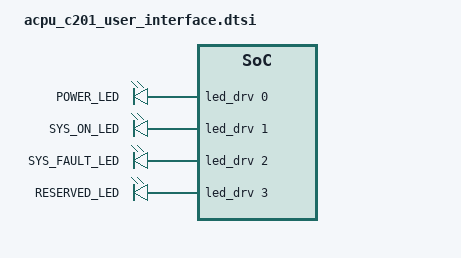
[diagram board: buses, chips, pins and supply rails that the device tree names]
/*
 * Copyright (c) 2021 Acme CPU
 *
 * SPDX-License-Identifier: Apache-2.0
 */

/ {
  ui-leds {
    compatible = "pwm-leds";

    p09_yellow_led: led-drv-0 {
      pwms = <&led_drv 0>;
      label = "POWER_LED";
    };

    p15_blue_led: led-drv-1 {
      pwms = <&led_drv 1>;
      label = "SYS_ON_LED";
    };

    p23_red_led: led-drv-2 {
      pwms = <&led_drv 2>;
      label = "SYS_FAULT_LED";
    };

    d11_green_led: led-drv-3 {
      pwms = <&led_drv 3>;
      label = "RESERVED_LED";
    };

  };
};


/*
 * This section describes parameters to initialize individual pins of the DIO_3 port expander with
 * during the system boots up. It is intended to be used by BSP GPIO Device Driver.
 */


/*
 *  Remaining pins of the DIO_3 port expander are dedicated to serve on-board peripheral devices.
 *  Description of those pins is presented in acme_cpu_c201_gpios.dtsi file
 */


&dio3_gpios {

    switch_1 {
      gpios = <&io_3 8 (GPIO_INPUT | GPIO_INT_EDGE_FALLING)>;
      label = "CHECK_SWITCH";
    };

    switch_2 {
      gpios = <&io_3 9 (GPIO_INPUT | GPIO_INT_EDGE_FALLING)>;
      label = "BACK_SWITCH";
    };

    switch_3 {
      gpios = <&io_3 10 (GPIO_INPUT | GPIO_INT_LEVEL_LOW)>;
      label = "LEFT_SWITCH";
    };

    switch_4 {
      gpios = <&io_3 11 (GPIO_INPUT | GPIO_INT_EDGE_FALLING)>;
      label = "POWER_SWITCH";
    };

    switch_5 {
      gpios = <&io_3 12 (GPIO_INPUT | GPIO_INT_LEVEL_LOW)>;
      label = "RIGHT_SWITCH";
    };

    switch_6 {
      gpios = <&io_3 13 (GPIO_INPUT | GPIO_INT_LEVEL_LOW)>;
      label = "DOWN_SWITCH";
    };

    switch_7 {
      gpios = <&io_3 14 (GPIO_INPUT | GPIO_INT_LEVEL_LOW)>;
      label = "UP_SWITCH";
    };

/*
    switch_8 {
      gpios = <&io_3 15 (GPIO_INPUT | GPIO_INT_DISABLE)>;
      label = "SHORT_TO_GROUND";
    };

 */

  };
